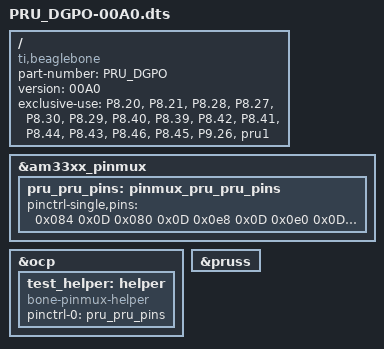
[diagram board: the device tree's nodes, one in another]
/* Device Tree Overlay for enabling 14 pins of PRU1 for direct output
* This overlay is based on the BB-BBBMINI-00A0.dts
* which can be found  in https://github.com/beagleboard/bb.org-overlays/blob/master/src/arm/BB-BBBMINI-00A0.dts
*
* Written by EGOR SPIRIDONOV for GPO-Tutorial
*/
/dts-v1/;
/plugin/;

/ {
   compatible = "ti,beaglebone", "ti,beaglebone-black";

   /* identification */
   part-number = "PRU_DGPO";
   version = "00A0";

   /* state the resources this cape uses */
   exclusive-use =
            /* PRU1 Direct Output */
            "P8.20", /* pru1: pr1_pru1_pru_r30_13 */
            "P8.21", /* pru1: pr1_pru1_pru_r30_12 */
            "P8.28", /* pru1: pr1_pru1_pru_r30_10 */
            "P8.27", /* pru1: pr1_pru1_pru_r30_8 */
            "P8.30", /* pru1: pr1_pru1_pru_r30_11 */
            "P8.29", /* pru1: pr1_pru1_pru_r30_9 */
            "P8.40", /* pru1: pr1_pru1_pru_r30_7 */
            "P8.39", /* pru1: pr1_pru1_pru_r30_6 */
            "P8.42", /* pru1: pr1_pru1_pru_r30_5 */
            "P8.41", /* pru1: pr1_pru1_pru_r30_4 */
            "P8.44", /* pru1: pr1_pru1_pru_r30_3 */
            "P8.43", /* pru1: pr1_pru1_pru_r30_2 */
            "P8.46", /* pru1: pr1_pru1_pru_r30_1 */
            "P8.45", /* pru1: pr1_pru1_pru_r30_0 */

            /* PRU1 Direct Input */
            "P9.26", /* pru1: pr1_pru1_pru_r31_16 */

            /* the hardware ip uses */
             "pru1";

   fragment@0 {
      target = <&am33xx_pinmux>;
      __overlay__ {

         pru_pru_pins: pinmux_pru_pru_pins {   // The PRU pin modes
            pinctrl-single,pins = <
                    0x084 0x0D   /* lcd_pclk.pr1_pru1_pru_r30_13, MODE5 | OUTPUT | PRU */
                    0x080 0x0D   /* lcd_pclk.pr1_pru1_pru_r30_12, MODE5 | OUTPUT | PRU */
                    0x0e8 0x0D   /* lcd_pclk.pr1_pru1_pru_r30_10, MODE5 | OUTPUT | PRU */
                    0x0e0 0x0D   /* lcd_vsync.pr1_pru1_pru_r30_8, MODE5 | OUTPUT | PRU */
                    0x0ec 0x0D   /* lcd_ac_bias_en.pr1_pru1_pru_r30_11, MODE5 | OUTPUT | PRU */
                    0x0e4 0x0D   /* lcd_hsync.pr1_pru1_pru_r30_9, MODE5 | OUTPUT | PRU */
                    0x0bc 0x0D   /* lcd_data7.pr1_pru1_pru_r30_7, MODE5 | OUTPUT | PRU */
                    0x0b8 0x0D   /* lcd_data6.pr1_pru1_pru_r30_6, MODE5 | OUTPUT | PRU */
                    0x0b4 0x0D   /* lcd_data5.pr1_pru1_pru_r30_5, MODE5 | OUTPUT | PRU */
                    0x0b0 0x0D   /* lcd_data4.pr1_pru1_pru_r30_4, MODE5 | OUTPUT | PRU */
                    0x0ac 0x0D   /* lcd_data3.pr1_pru1_pru_r30_3, MODE5 | OUTPUT | PRU */
                    0x0a8 0x0D   /* lcd_data2.pr1_pru1_pru_r30_2, MODE5 | OUTPUT | PRU */
                    0x0a4 0x0D   /* lcd_data1.pr1_pru1_pru_r30_1, MODE5 | OUTPUT | PRU */
                    0x0a0 0x0D   /* lcd_data0.pr1_pru1_pru_r30_0, MODE5 | OUTPUT | PRU */

                    0x0a0 0x36   /* uart1_rxd.pr1_pru1_pru_r31_16, MODE6 | INPUT | PRU */
            >;
         };
      };
   };

  fragment@1 {
    target = <&ocp>;
    __overlay__ {
      test_helper: helper {
        compatible = "bone-pinmux-helper";
        pinctrl-names = "default";
        pinctrl-0 = <&pru_pru_pins>;
        status = "okay";
      };
    };
  };

   fragment@2 {         // Enable the PRUSS
      target = <&pruss>;
      __overlay__ {
         status = "okay";
      };
   };
};
